VERSION ""

NS_ :

BS_:

BU_:

BO_ 2147487778 status: 2 Vector__XXX
 SG_ over_rev : 7|1@0+ (1,0) [0|0] "boolean" Vector__XXX

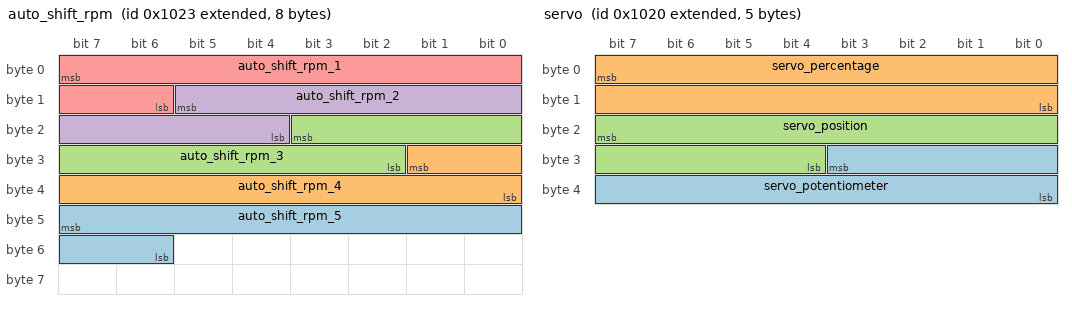
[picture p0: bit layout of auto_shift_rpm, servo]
BO_ 2147487779 auto_shift_rpm: 8 Vector__XXX
 SG_ auto_shift_rpm_5 : 47|10@0+ (12,10000) [10000|22276] "RPM" Vector__XXX
 SG_ auto_shift_rpm_4 : 25|10@0+ (12,10000) [10000|22276] "RPM" Vector__XXX
 SG_ auto_shift_rpm_3 : 19|10@0+ (12,10000) [10000|22276] "RPM" Vector__XXX
 SG_ auto_shift_rpm_2 : 13|10@0+ (12,10000) [10000|22276] "RPM" Vector__XXX
 SG_ auto_shift_rpm_1 : 7|10@0+ (12,10000) [10000|22276] "RPM" Vector__XXX

BO_ 2147487776 servo: 5 Vector__XXX
 SG_ servo_potentiometer : 27|12@0+ (0.00122100122,0) [0|0] "v" Vector__XXX
 SG_ servo_percentage : 7|16@0+ (1,0) [0|0] "%" Vector__XXX
 SG_ servo_position : 23|12@0+ (1,0) [0|0] "us" Vector__XXX

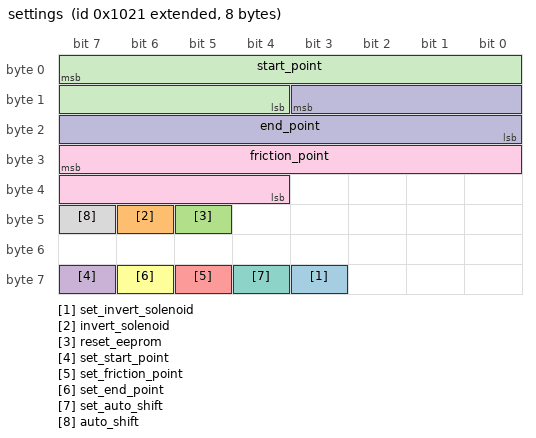
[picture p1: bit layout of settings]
BO_ 2147487777 settings: 8 Vector__XXX
 SG_ set_invert_solenoid : 59|1@0+ (1,0) [0|0] "" Vector__XXX
 SG_ invert_solenoid : 46|1@0+ (1,0) [0|0] "" Vector__XXX
 SG_ reset_eeprom : 45|1@0+ (1,0) [0|0] "" Vector__XXX
 SG_ set_start_point : 63|1@0+ (1,0) [0|0] "boolean" Vector__XXX
 SG_ set_friction_point : 61|1@0+ (1,0) [0|0] "boolean" Vector__XXX
 SG_ set_end_point : 62|1@0+ (1,0) [0|0] "boolean" Vector__XXX
 SG_ set_auto_shift : 60|1@0+ (1,0) [0|0] "boolean" Vector__XXX
 SG_ auto_shift : 47|1@0+ (1,0) [0|0] "boolean" Vector__XXX
 SG_ friction_point : 31|12@0+ (1,0) [0|0] "microseconds" Vector__XXX
 SG_ end_point : 11|12@0+ (1,0) [0|0] "microseconds" Vector__XXX
 SG_ start_point : 7|12@0+ (1,0) [0|0] "microseconds" Vector__XXX

BA_DEF_  "BusType" STRING ;
BA_DEF_ BO_  "GenMsgCycleTime" INT 0 0;
BA_DEF_DEF_  "BusType" "CAN";
BA_DEF_DEF_  "GenMsgCycleTime" 0;
BA_ "GenMsgCycleTime" BO_ 2147487779 1000;
BA_ "GenMsgCycleTime" BO_ 2147487776 20;
BA_ "GenMsgCycleTime" BO_ 2147487777 200;
